AUTOSAR XML (schema 4-2-2)
package /BMW/Platform/Rmh/SwcImplementations
  swc implementation Rmh_Cdd_Implementation: behavior=InternalBehavior
    code-descriptors:
      code CodeDescriptor: artifact-descriptors=autosar-engineering-object={short-label=Default, category=SWSRC}
package /BMW/Platform/Rmh/SwComponentTypes
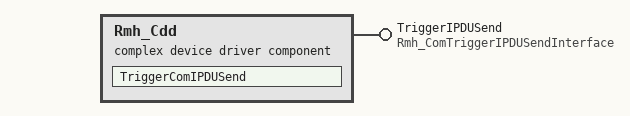
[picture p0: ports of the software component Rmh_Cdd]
  complex device driver sw component type Rmh_Cdd
    provide port TriggerIPDUSend: server-com-spec{operation=Rmh_TriggerComIPDUSend, queue-length=1}, provided-interface=Rmh_ComTriggerIPDUSendInterface
    behavior InternalBehavior: port-api-option{enable-take-address=false, error-handling=NO-TRANSFORMER-ERROR-HANDLING, indirect-api=false, port=TriggerIPDUSend}
      operation invoked event OperationInvokedEvent: start-on-event=TriggerComIPDUSend, operation=TriggerIPDUSend.Rmh_TriggerComIPDUSend
      runnable TriggerComIPDUSend: symbol=Rmh_TriggerComIPDUSend
